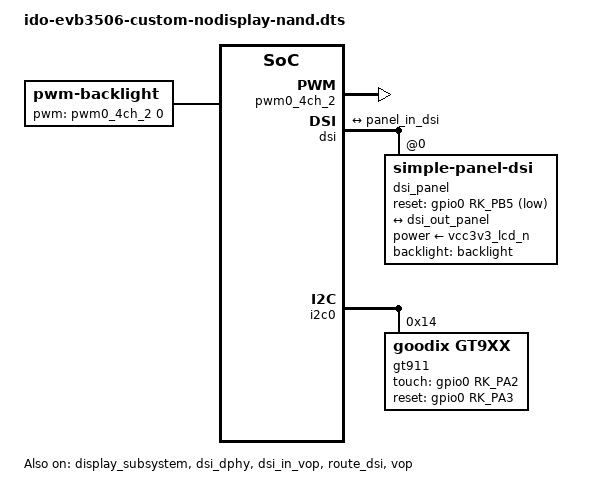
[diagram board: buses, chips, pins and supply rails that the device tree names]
// SPDX-License-Identifier: (GPL-2.0+ OR MIT)
/*
 * Copyright (c) 2024 Rockchip Electronics Co., Ltd.
 */


#include <dt-bindings/display/drm_mipi_dsi.h>
#include <dt-bindings/input/rk-input.h>
#include <dt-bindings/suspend/rockchip-rk3506.h>
#include "ido-evb3506-v1a-nand.dtsi"

/ {
	backlight: backlight {
		compatible = "pwm-backlight";
		pwms = <&pwm0_4ch_2 0 25000 0>;
		brightness-levels = <
			  0  20  20  21  21  22  22  23
			 23  24  24  25  25  26  26  27
			 27  28  28  29  29  30  30  31
			 31  32  32  33  33  34  34  35
			 35  36  36  37  37  38  38  39
			 40  41  42  43  44  45  46  47
			 48  49  50  51  52  53  54  55
			 56  57  58  59  60  61  62  63
			 64  65  66  67  68  69  70  71
			 72  73  74  75  76  77  78  79
			 80  81  82  83  84  85  86  87
			 88  89  90  91  92  93  94  95
			 96  97  98  99 100 101 102 103
			104 105 106 107 108 109 110 111
			112 113 114 115 116 117 118 119
			120 121 122 123 124 125 126 127
			128 129 130 131 132 133 134 135
			136 137 138 139 140 141 142 143
			144 145 146 147 148 149 150 151
			152 153 154 155 156 157 158 159
			160 161 162 163 164 165 166 167
			168 169 170 171 172 173 174 175
			176 177 178 179 180 181 182 183
			184 185 186 187 188 189 190 191
			192 193 194 195 196 197 198 199
			200 201 202 203 204 205 206 207
			208 209 210 211 212 213 214 215
			216 217 218 219 220 221 222 223
			224 225 226 227 228 229 230 231
			232 233 234 235 236 237 238 239
			240 241 242 243 244 245 246 247
			248 249 250 251 252 253 254 255
		>;
		default-brightness-level = <200>;
		status = "okay";
	};
};


&display_subsystem {
	logo-memory-region = <&drm_logo>;
	status = "okay";
};

&pwm0_4ch_2 {
        pinctrl-names = "active";
        pinctrl-0 = <&rm_io4_pwm0_ch2>;
        status = "okay";
};

&dsi {
	status = "okay";
	//rockchip,lane-rate = <850>;
	dsi_panel: panel@0 {
		status = "okay";
		compatible = "simple-panel-dsi";
		reg = <0>;
		backlight = <&backlight>;
		reset-gpios  = <&gpio0 RK_PB5 GPIO_ACTIVE_LOW>;
		prepare-delay-ms = <5>;
		reset-delay-ms = <1>;
		init-delay-ms = <80>;
		disable-delay-ms = <10>;
		unprepare-delay-ms = <5>;

		width-mm = <68>;
		height-mm = <121>;

		dsi,flags = <(MIPI_DSI_MODE_VIDEO | MIPI_DSI_MODE_VIDEO_BURST |
			      MIPI_DSI_MODE_LPM | MIPI_DSI_MODE_NO_EOT_PACKET)>;
		dsi,format = <MIPI_DSI_FMT_RGB888>;
		dsi,lanes  = <2>;
		panel-init-sequence = [
			39 00 04 B9 F1 12 87
			39 00 04 B2 B4 03 70
			39 00 0B B3 10 10 28 28 03 FF 00 00 00 00
			15 00 02 B4 80
			39 00 03 B5 0A 0A
			39 00 03 B6 8D 8D
			39 00 05 B8 26 22 F0 13
			39 00 1C BA 31 81 05 F9 0E 0E 20 00 00 00 00 00 00 00 44 25 00 91 0A 00 00 01 4F 01 00 00 37
			15 00 02 BC 47
			39 00 06 BF 02 10 00 80 04
			39 00 0A C0 73 73 50 50 00 00 12 73 00
			39 00 12 C1 36 00 32 32 77 E1 77 77 CC CC FF FF 11 11 00 00 32
			39 00 0D C7 10 00 0A 00 00 00 00 00 ED C5 00 A5
			39 00 05 C8 10 40 1E 03
			15 00 02 CC 0B
			39 00 23 E0 00 0A 0F 2A 33 3F 44 39 06 0C 0E 14 15 13 15 10 18 00 0A 0F 2A 33 3F 44 39 06 0C 0E 14 15 13 15 10 18
			39 00 08 E1 11 11 91 00 00 00 00
			39 00 0F E3 07 07 0B 0B 0B 0B 00 00 00 00 FF 04 C0 10
			39 00 40 E9 C8 10 0A 00 00 80 81 12 31 23 4F 86 A0 00 47 08 00 00 0C 00 00 00 00 00 0C 00 00 00 98 02 8B AF 46 02 88 88 88 88 88 98 13 8B AF 57 13 88 88 88 88 88 00 00 00 00 00 00 00 00 00 00 00 00 00 
			39 00 3E EA 97 0C 09 09 09 78 00 00 00 00 00 00 9F 31 8B A8 31 75 88 88 88 88 88 9F 20 8B A8 20 64 88 88 88 88 88 23 00 00 02 71 00 00 00 00 00 00 00 00 00 00 00 00 00 00 00 40 80 81 00 00 00 00
			39 00 04 EF FF FF 01
			05 96 01 11
			05 14 01 29
		];

		disp_timings0: display-timings {
			native-mode = <&dsi_timing0>;
			dsi_timing0: timing0 {
				clock-frequency = <48000000>;
				hactive = <720>;
				vactive = <720>;
				hfront-porch = <106>;
				hsync-len = <8>;
				hback-porch = <120>;
				vfront-porch = <20>;
				vsync-len = <4>;
				vback-porch = <20>;
				hsync-active = <0>;
				vsync-active = <0>;
				de-active = <0>;
				pixelclk-active = <0>;
			};
		};

		ports {
			#address-cells = <1>;
			#size-cells = <0>;

			port@0 {
				reg = <0>;
				panel_in_dsi: endpoint {
					remote-endpoint = <&dsi_out_panel>;
				};
			};
		};
	};

	ports {
		#address-cells = <1>;
		#size-cells = <0>;

		port@1 {
			reg = <1>;
			dsi_out_panel: endpoint {
				remote-endpoint = <&panel_in_dsi>;
			};
		};
	};

};

&dsi_dphy {
    status = "okay";
};

&dsi_in_vop {
	status = "okay";
};

&dsi_panel {
	power-supply = <&vcc3v3_lcd_n>;
};

&route_dsi{
        status = "okay";
		connect = <&vop_out_dsi>;
};

&i2c0 {
	status = "okay";
	pinctrl-names = "default";
	pinctrl-0 = <&rm_io0_i2c0_scl
		     &rm_io1_i2c0_sda>;

	gt911@14 {
		compatible = "goodix,gt9xx";
		reg = <0x14>;
		pinctrl-0 = <&touch_gpio>;
		touch-gpio = <&gpio0 RK_PA2 IRQ_TYPE_LEVEL_LOW>;
		reset-gpio = <&gpio0 RK_PA3 GPIO_ACTIVE_HIGH>;
		max-x = <720>;
		max-y = <720>;
		tp-size = <9110>;
		status = "okay";
	};
};

&vop {
	status = "okay";
};

&pinctrl {
	touch {
		touch_gpio: touch-gpio {
			rockchip,pins = <0 RK_PA2 RK_FUNC_GPIO &pcfg_pull_none>;
		};
		
		reset_gpio: reset-gpio {
			rockchip,pins = <0 RK_PA3 RK_FUNC_GPIO &pcfg_pull_none>;
		};
	};
};
